# STM32G553xx register map
File version: 1.0
Registers are 32-bit, read-write, reset 0x0 unless marked. A register's access mark holds for its fields unless they carry their own. Offsets are from the block's base; [hi:lo] are bit positions.

## RSSLIB_PFUNC — RSSLib function pointer structure
Base 0x0BFADB68
0x00 DataProvisioning ro
0x10 JumpHDPLvl2 ro
0x14 JumpHDPLvl3 ro
0x18 JumpHDPLvl3NS ro

## NSSLIB_PFUNC — RSSLib secure callable function pointer structure
Base 0x0BFADB6C
0x00 JumpHDPLvl2 ro
0x04 JumpHDPLvl3 ro

## WWDG — System window watchdog (WWDG)
Base 0x40003000
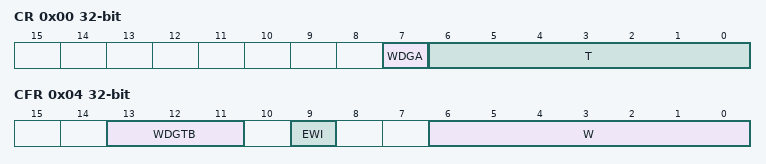
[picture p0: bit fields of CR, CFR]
0x00 CR — WWDG control register
  [7] WDGA — Activation bit
  [6:0] T — 7-bit counter (MSB to LSB)
0x04 CFR — WWDG configuration register
  [13:11] WDGTB — Timer base
  [9] EWI — Early wake-up interrupt enable
  [6:0] W — 7-bit window value
0x08 SR — WWDG status register
  [0] EWIF — Early wake-up interrupt flag

## IWDG — Independent watchdog (IWDG)
Base 0x40003400
0x00 KR — IWDG key register
  [15:0] KEY — Key value (write only, read 0x0000)
0x04 PR — IWDG prescaler register
  [3:0] PR — Prescaler divider
0x08 RLR — IWDG reload register
  [11:0] RL — Watchdog counter reload value
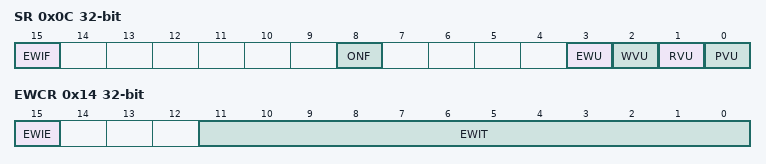
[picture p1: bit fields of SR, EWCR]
0x0C SR ro — IWDG status register
  [15] EWIF — Watchdog early interrupt flag
  [8] ONF — Watchdog enable status bit
  [3] EWU — Watchdog interrupt comparator value update
  [2] WVU — Watchdog counter window value update
  [1] RVU — Watchdog counter reload value update
  [0] PVU — Watchdog prescaler value update
0x10 WINR — IWDG window register
  [11:0] WIN — Watchdog counter window value
0x14 EWCR — IWDG early wake-up interrupt register
  [15] EWIE — Watchdog early interrupt enable
  [11:0] EWIT — Watchdog counter early wake-up interrupt value
0x18 ICR — IWDG interrupt clear register
  [15] EWIC — Watchdog early interrupt acknowledge

## I2C1 — Inter-integrated circuit interface (I2C)
Base 0x40005400
Same registers: I2C2 0x40005800, I2C3 0x44002800, I2C4 0x44002C00
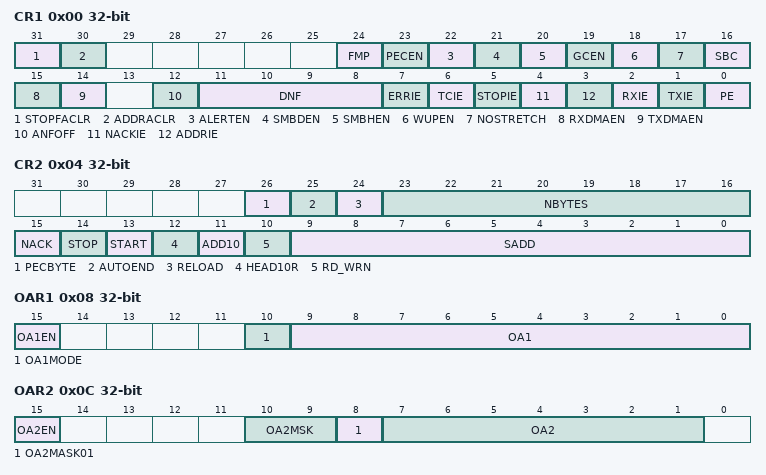
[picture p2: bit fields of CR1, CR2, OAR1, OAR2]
0x00 CR1 — I2C control register 1
  [31] STOPFACLR
  [30] ADDRACLR
  [24] FMP — Fast-mode Plus drive enable
  [23] PECEN — PEC enable
  [22] ALERTEN — SMBus alert enable
  [21] SMBDEN — SMBus device default address enable
  [20] SMBHEN — SMBus host address enable
  [19] GCEN — General call enable
  [18] WUPEN — Wake-up from Stop mode enable
  [17] NOSTRETCH — Clock stretching disable
  [16] SBC — Target byte control
  [15] RXDMAEN — DMA reception requests enable
  [14] TXDMAEN — DMA transmission requests enable
  [12] ANFOFF — Analog noise filter OFF
  [11:8] DNF — Digital noise filter
  [7] ERRIE — Error interrupts enable
  [6] TCIE — Transfer complete interrupt enable
  [5] STOPIE — STOP detection interrupt enable
  [4] NACKIE
  [3] ADDRIE
  [2] RXIE — RX interrupt enable
  [1] TXIE — TX interrupt enable
  [0] PE — Peripheral enable
0x04 CR2 — I2C control register 2
  [26] PECBYTE — Packet error checking byte
  [25] AUTOEND — Automatic end mode (controller mode)
  [24] RELOAD — NBYTES reload mode
  [23:16] NBYTES — Number of bytes
  [15] NACK — NACK generation (target mode)
  [14] STOP — STOP condition generation
  [13] START — START condition generation
  [12] HEAD10R
  [11] ADD10
  [10] RD_WRN — Transfer direction (controller mode)
  [9:0] SADD — Target address (controller mode)
0x08 OAR1 — I2C own address 1 register
  [15] OA1EN — Own address 1 enable
  [10] OA1MODE — Own address 1 10-bit mode
  [9:0] OA1 — Interface own target address
0x0C OAR2 — I2C own address 2 register
  [15] OA2EN — Own address 2 enable
  [10:9] OA2MSK — Own address 2 masks
  [8] OA2MASK01
  [7:1] OA2 — Interface address
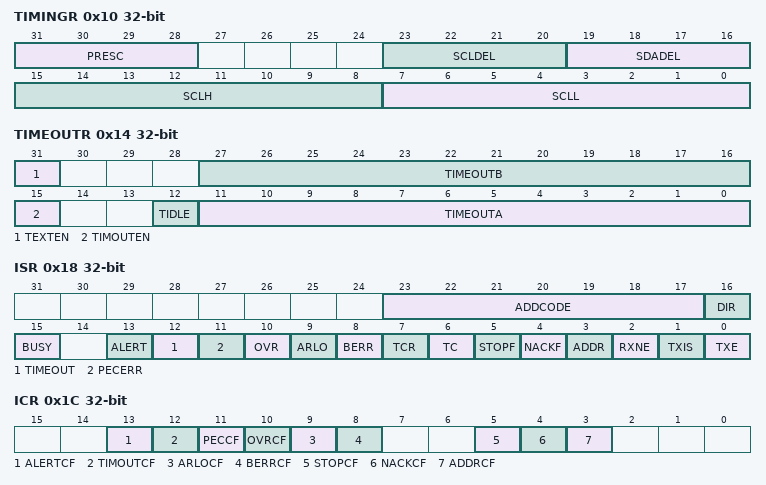
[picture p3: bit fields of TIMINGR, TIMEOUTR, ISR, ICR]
0x10 TIMINGR — I2C timing register
  [31:28] PRESC — Timing prescaler
  [23:20] SCLDEL — Data setup time
  [19:16] SDADEL — Data hold time
  [15:8] SCLH — SCL high period (controller mode)
  [7:0] SCLL — SCL low period (controller mode)
0x14 TIMEOUTR — I2C timeout register
  [31] TEXTEN — Extended clock timeout enable
  [27:16] TIMEOUTB — Bus timeout B
  [15] TIMOUTEN — Clock timeout enable
  [12] TIDLE — Idle clock timeout detection
  [11:0] TIMEOUTA — Bus timeout A
0x18 ISR — I2C interrupt and status register
  [23:17] ADDCODE — Address match code (target mode)
  [16] DIR — Transfer direction (target mode)
  [15] BUSY — Bus busy
  [13] ALERT — SMBus alert
  [12] TIMEOUT
  [11] PECERR — PEC error in reception
  [10] OVR — Overrun/underrun (target mode)
  [9] ARLO — Arbitration lost
  [8] BERR — Bus error
  [7] TCR — Transfer complete reload
  [6] TC — Transfer complete (controller mode)
  [5] STOPF — STOP detection flag
  [4] NACKF — Not acknowledge received flag
  [3] ADDR — Address matched (target mode)
  [2] RXNE
  [1] TXIS
  [0] TXE
0x1C ICR — I2C interrupt clear register
  [13] ALERTCF — Alert flag clear
  [12] TIMOUTCF — Timeout detection flag clear
  [11] PECCF — PEC error flag clear
  [10] OVRCF — Overrun/underrun flag clear
  [9] ARLOCF — Arbitration lost flag clear
  [8] BERRCF — Bus error flag clear
  [5] STOPCF — STOP detection flag clear
  [4] NACKCF — Not acknowledge flag clear
  [3] ADDRCF — Address matched flag clear
0x20 PECR ro — I2C PEC register
  [7:0] PEC — Packet error checking register
0x24 RXDR ro — I2C receive data register
  [7:0] RXDATA — 8-bit receive data
0x28 TXDR — I2C transmit data register
  [7:0] TXDATA — 8-bit transmit data
